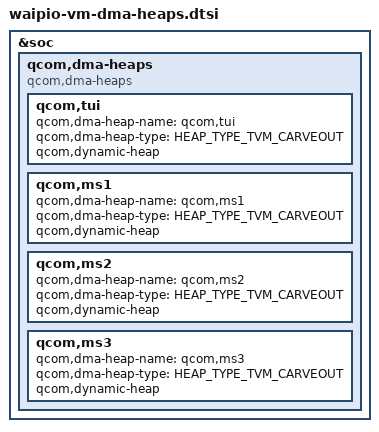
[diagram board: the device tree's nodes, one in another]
// SPDX-License-Identifier: BSD-3-Clause
/*
 * Copyright (c) Qualcomm Technologies, Inc. and/or its subsidiaries.
 */

#include <dt-bindings/arm/msm/qcom_dma_heap_dt_constants.h>

&soc {
	qcom,dma-heaps {
		compatible = "qcom,dma-heaps";

		qcom,tui {
			qcom,dma-heap-name = "qcom,tui";
			qcom,dma-heap-type = <HEAP_TYPE_TVM_CARVEOUT>;
			qcom,dynamic-heap;
		};

		qcom,ms1 {
			qcom,dma-heap-name = "qcom,ms1";
			qcom,dma-heap-type = <HEAP_TYPE_TVM_CARVEOUT>;
			qcom,dynamic-heap;
		};

		qcom,ms2 {
			qcom,dma-heap-name = "qcom,ms2";
			qcom,dma-heap-type = <HEAP_TYPE_TVM_CARVEOUT>;
			qcom,dynamic-heap;
		};

		qcom,ms3 {
			qcom,dma-heap-name = "qcom,ms3";
			qcom,dma-heap-type = <HEAP_TYPE_TVM_CARVEOUT>;
			qcom,dynamic-heap;
		};
	};
};
